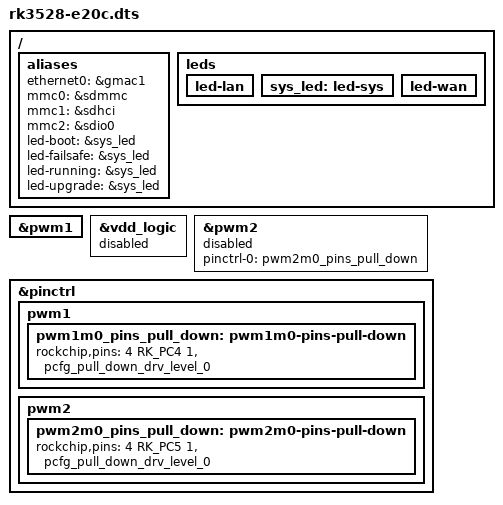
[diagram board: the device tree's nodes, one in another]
/dts-v1/;

#include <rockchip/rk3528-radxa-e20c.dts>

/ {
	aliases {
		ethernet0 = &gmac1;

		mmc0 = &sdmmc;
		mmc1 = &sdhci;
		mmc2 = &sdio0;

		led-boot = &sys_led;
		led-failsafe = &sys_led;
		led-running = &sys_led;
		led-upgrade = &sys_led;
	};

	leds {

		led-lan {

		};

		sys_led: led-sys {

		};

		led-wan {

		};
	};
};

&pwm1 {
	status = "okay";
};

// pwm2 hangs system, disable it
&vdd_logic {
	status = "disabled";
};

&pwm2 {
	pinctrl-0 = <&pwm2m0_pins_pull_down>;
	status = "disabled";
};

&pinctrl {
	pwm1 {
		pwm1m0_pins_pull_down: pwm1m0-pins-pull-down {
			rockchip,pins =
				/* pwm1_m0 */
				<4 RK_PC4 1 &pcfg_pull_down_drv_level_0>;
		};
	};
	pwm2 {
		pwm2m0_pins_pull_down: pwm2m0-pins-pull-down {
			rockchip,pins =
				/* pwm2_m0 */
				<4 RK_PC5 1 &pcfg_pull_down_drv_level_0>;
		};
	};
};
